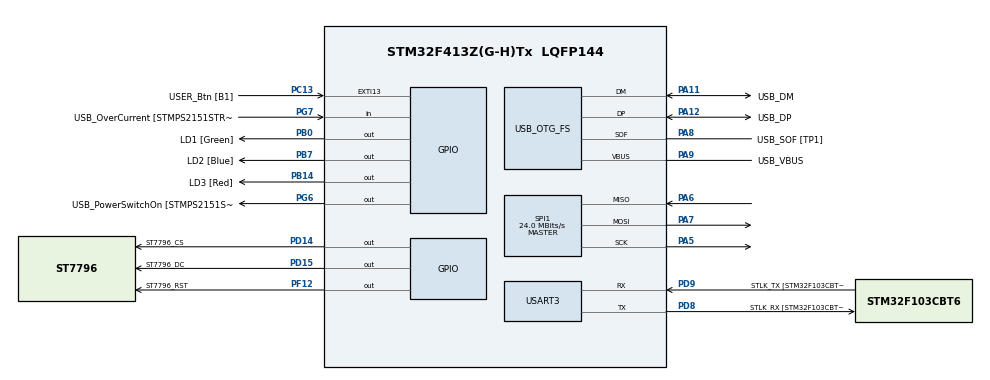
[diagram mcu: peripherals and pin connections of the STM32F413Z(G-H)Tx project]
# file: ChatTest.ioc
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Mcu.Family=STM32F4
Mcu.Name=STM32F413Z(G-H)Tx
Mcu.Package=LQFP144
NVIC.PriorityGroup=NVIC_PRIORITYGROUP_4
PA10.GPIO_Label=USB_ID
PA10.Signal=USB_OTG_FS_ID
PA11.GPIO_Label=USB_DM
PA11.Mode=Device_Only
PA11.Signal=USB_OTG_FS_DM
PA12.GPIO_Label=USB_DP
PA12.Mode=Device_Only
PA12.Signal=USB_OTG_FS_DP
PA13.GPIO_Label=TMS
PA13.Mode=Serial_Wire
PA13.Signal=SYS_JTMS-SWDIO
PA14.GPIO_Label=TCK
PA14.Mode=Serial_Wire
PA14.Signal=SYS_JTCK-SWCLK
PA5.Mode=Full_Duplex_Master
PA5.Signal=SPI1_SCK
PA6.Mode=Full_Duplex_Master
PA6.Signal=SPI1_MISO
PA7.Mode=Full_Duplex_Master
PA7.Signal=SPI1_MOSI
PA8.GPIO_Label=USB_SOF [TP1]
PA8.Mode=Activate_SOF_FS
PA8.Signal=USB_OTG_FS_SOF
PA9.GPIO_Label=USB_VBUS
PA9.Mode=Activate_VBUS
PA9.Signal=USB_OTG_FS_VBUS
PB0.GPIO_Label=LD1 [Green]
PB0.Signal=GPIO_Output
PB14.GPIO_Label=LD3 [Red]
PB14.Signal=GPIO_Output
PB3.GPIO_Label=SWO
PB3.Signal=SYS_JTDO-SWO
PB7.GPIO_Label=LD2 [Blue]
PB7.Signal=GPIO_Output
PC13.GPIO_Label=USER_Btn [B1]
PC13.Signal=GPXTI13
PC14-OSC32_IN.Mode=LSE-External-Oscillator
PC14-OSC32_IN.Signal=RCC_OSC32_IN
PC15-OSC32_OUT.Mode=LSE-External-Oscillator
PC15-OSC32_OUT.Signal=RCC_OSC32_OUT
PD14.GPIO_Label=ST7796_CS
PD14.Signal=GPIO_Output
PD15.GPIO_Label=ST7796_DC
PD15.Signal=GPIO_Output
PD8.GPIO_Label=STLK_RX [STM32F103CBT6_PA3]
PD8.Mode=Asynchronous
PD8.Signal=USART3_TX
PD9.GPIO_Label=STLK_TX [STM32F103CBT6_PA2]
PD9.Mode=Asynchronous
PD9.Signal=USART3_RX
PF12.GPIO_Label=ST7796_RST
PF12.Signal=GPIO_Output
PG6.GPIO_Label=USB_PowerSwitchOn [STMPS2151STR_EN]
PG6.Signal=GPIO_Output
PG7.GPIO_Label=USB_OverCurrent [STMPS2151STR_FAULT]
PG7.Signal=GPIO_Input
PH0\ -\ OSC_IN.GPIO_Label=MCO
PH0\ -\ OSC_IN.Mode=HSE-External-Clock-Source
PH0\ -\ OSC_IN.Signal=RCC_OSC_IN
PH1\ -\ OSC_OUT.Mode=HSE-External-Clock-Source
PH1\ -\ OSC_OUT.Signal=RCC_OSC_OUT
ProjectManager.HeapSize=0x200
ProjectManager.StackSize=0x400
ProjectManager.TargetToolchain=CMake
RCC.48MHZClocksFreq_Value=24000000
RCC.AHBFreq_Value=96000000
RCC.APB1CLKDivider=RCC_HCLK_DIV2
RCC.APB1Freq_Value=48000000
RCC.APB1TimFreq_Value=96000000
RCC.APB2Freq_Value=96000000
RCC.APB2TimFreq_Value=96000000
RCC.CortexFreq_Value=96000000
RCC.HCLKFreq_Value=96000000
RCC.HSE_VALUE=8000000
RCC.HSI_VALUE=16000000
RCC.PLLM=8
RCC.PLLMUL=RCC_PLL_MUL9
RCC.PLLN=384
RCC.PLLP=RCC_PLLP_DIV4
RCC.PLLQ=8
RCC.PRESCALERUSB=RCC_USBCLKSOURCE_PLL_DIV1_5
RCC.SYSCLKFreq_VALUE=96000000
RCC.SYSCLKSource=RCC_SYSCLKSOURCE_PLLCLK
RCC.SYSCLKSourceVirtual=RCC_SYSCLKSOURCE_PLLCLK
RCC.USBFreq_Value=48000000
RCC.VCOOutputFreq_Value=384000000
SPI1.BaudRatePrescaler=SPI_BAUDRATEPRESCALER_4
SPI1.CLKPhase=SPI_PHASE_1EDGE
SPI1.CLKPolarity=SPI_POLARITY_LOW
SPI1.CalculateBaudRate=24.0 MBits/s
SPI1.DataSize=SPI_DATASIZE_8BIT
SPI1.Direction=SPI_DIRECTION_2LINES
SPI1.FirstBit=SPI_FIRSTBIT_MSB
SPI1.Mode=SPI_MODE_MASTER
SPI1.NSS=SPI_NSS_SOFT
SPI1.VirtualType=VM_MASTER
USART3.VirtualMode=VM_ASYNC
USB_OTG_FS.VirtualMode=Device_Only
board=NUCLEO-F413ZH

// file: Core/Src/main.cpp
// Main application entry point and runtime-owned state.

/* USER CODE BEGIN Header */
/**
  ******************************************************************************
   * @file           : main.cpp
  * @brief          : Main program body
  ******************************************************************************
  * @attention
  *
  * Copyright (c) 2026 STMicroelectronics.
  * All rights reserved.
  *
  * This software is licensed under terms that can be found in the LICENSE file
  * in the root directory of this software component.
  * If no LICENSE file comes with this software, it is provided AS-IS.
  *
  ******************************************************************************
  */
/* USER CODE END Header */
#include "main.h"

/* USER CODE BEGIN Includes */
#include "app/app_runtime.h"
#include "app/app_startup.h"
/* USER CODE END Includes */

SPI_HandleTypeDef hspi1;

UART_HandleTypeDef huart3;

PCD_HandleTypeDef hpcd_USB_OTG_FS;

/* USER CODE BEGIN PV */
DMA_HandleTypeDef hdma_spi1_tx;
/* USER CODE END PV */

void SystemClock_Config(void);
static void MX_GPIO_Init(void);
static void MX_SPI1_Init(void);
static void MX_USART3_UART_Init(void);
static void MX_USB_OTG_FS_PCD_Init(void);

/* USER CODE BEGIN 0 */

extern "C" int __io_putchar(int ch)
{
  uint8_t byte = (uint8_t)ch;

  /* printf is routed to the ST-LINK virtual COM port when USART3 is alive,
   * giving lightweight debug output without involving the MIDI UART path. */
  if (huart3.Instance == USART3)
    HAL_UART_Transmit(&huart3, &byte, 1U, 10U);

  return ch;
}

/* USER CODE END 0 */

int main(void)
{

  /* MCU Configuration--------------------------------------------------------*/

  /* Reset of all peripherals, Initializes the Flash interface and the Systick. */
    HAL_Init();

  /* Configure the system clock */
  SystemClock_Config();

  /* Initialize all configured peripherals */
  MX_GPIO_Init();
  MX_SPI1_Init();
  MX_USART3_UART_Init();
  MX_USB_OTG_FS_PCD_Init();
  /* USER CODE BEGIN 2 */
  /* Board/application startup owns the higher-level hardware bring-up that
   * CubeMX does not model: runtime state, display, MIDI, storage, and UI. */
  AppStartup_Run();

  /* USER CODE END 2 */

  /* Infinite loop */
  while (1)
  {
    /* Keep the foreground loop thin so time-sensitive work can stay in the
     * app runtime/service layers instead of spreading through main(). */
    AppRuntime_ServiceForeground();
  }
}

static void MX_SPI1_Init(void)
{

  hspi1.Instance = SPI1;
  hspi1.Init.Mode = SPI_MODE_MASTER;
  hspi1.Init.Direction = SPI_DIRECTION_2LINES;
  hspi1.Init.DataSize = SPI_DATASIZE_8BIT;
  hspi1.Init.CLKPolarity = SPI_POLARITY_LOW;
  hspi1.Init.CLKPhase = SPI_PHASE_1EDGE;
  hspi1.Init.NSS = SPI_NSS_SOFT;
  hspi1.Init.BaudRatePrescaler = SPI_BAUDRATEPRESCALER_2;
  hspi1.Init.FirstBit = SPI_FIRSTBIT_MSB;
  hspi1.Init.TIMode = SPI_TIMODE_DISABLE;
  hspi1.Init.CRCCalculation = SPI_CRCCALCULATION_DISABLE;
  hspi1.Init.CRCPolynomial = 10;
  if (HAL_SPI_Init(&hspi1) != HAL_OK)
  {
    Error_Handler();
  }
}

void SystemClock_Config(void)
{
  /** Configure the main internal regulator output voltage */
  __HAL_RCC_PWR_CLK_ENABLE();
  __HAL_PWR_VOLTAGESCALING_CONFIG(PWR_REGULATOR_VOLTAGE_SCALE1);

  /* Boot from HSI first so standalone E5V startup does not depend on the
   * ST-LINK-side MCO becoming ready before main() runs. */
  if (AppStartup_RestoreHsiPll() != HAL_OK)
  {
    Error_Handler();
  }
}

static void MX_USART3_UART_Init(void)
{

  /* USER CODE BEGIN USART3_Init 1 */
 // This is the UART used for debug prints over the ST-Link USB interface. It is not used for MIDI output, which is brought up by the board-startup module before the UI starts sending MIDI messages.
  /* USER CODE END USART3_Init 1 */
  huart3.Instance = USART3;
  huart3.Init.BaudRate = 115200;
  huart3.Init.WordLength = UART_WORDLENGTH_8B;
  huart3.Init.StopBits = UART_STOPBITS_1;
  huart3.Init.Parity = UART_PARITY_NONE;
  huart3.Init.Mode = UART_MODE_TX_RX;
  huart3.Init.HwFlowCtl = UART_HWCONTROL_NONE;
  huart3.Init.OverSampling = UART_OVERSAMPLING_16;
  if (HAL_UART_Init(&huart3) != HAL_OK)
  {
    Error_Handler();
  }

}

static void MX_USB_OTG_FS_PCD_Init(void)
{

  hpcd_USB_OTG_FS.Instance = USB_OTG_FS;
  hpcd_USB_OTG_FS.Init.dev_endpoints = 6;
  hpcd_USB_OTG_FS.Init.speed = PCD_SPEED_FULL;
  hpcd_USB_OTG_FS.Init.dma_enable = DISABLE;
  hpcd_USB_OTG_FS.Init.phy_itface = PCD_PHY_EMBEDDED;
  hpcd_USB_OTG_FS.Init.Sof_enable = ENABLE;
  hpcd_USB_OTG_FS.Init.low_power_enable = DISABLE;
  hpcd_USB_OTG_FS.Init.lpm_enable = DISABLE;
  hpcd_USB_OTG_FS.Init.battery_charging_enable = ENABLE;
  hpcd_USB_OTG_FS.Init.vbus_sensing_enable = ENABLE;
  hpcd_USB_OTG_FS.Init.use_dedicated_ep1 = DISABLE;
  if (HAL_PCD_Init(&hpcd_USB_OTG_FS) != HAL_OK)
  {
    Error_Handler();
  }

}

static void MX_GPIO_Init(void)
{
  GPIO_InitTypeDef GPIO_InitStruct = {0};

  /* GPIO Ports Clock Enable */
  __HAL_RCC_GPIOC_CLK_ENABLE();
  __HAL_RCC_GPIOH_CLK_ENABLE();
  __HAL_RCC_GPIOB_CLK_ENABLE();
  __HAL_RCC_GPIOD_CLK_ENABLE();
  __HAL_RCC_GPIOE_CLK_ENABLE();
  __HAL_RCC_GPIOF_CLK_ENABLE();
  __HAL_RCC_GPIOG_CLK_ENABLE();
  __HAL_RCC_GPIOA_CLK_ENABLE();

  /*Configure GPIO pin Output Level */
  HAL_GPIO_WritePin(GPIOB, LD1_Pin|LD3_Pin|LD2_Pin, GPIO_PIN_RESET);

  /*Configure GPIO pin Output Level */
  HAL_GPIO_WritePin(USB_PowerSwitchOn_GPIO_Port, USB_PowerSwitchOn_Pin, GPIO_PIN_RESET);

  /*Configure GPIO pins : LD1_Pin LD3_Pin LD2_Pin */
  GPIO_InitStruct.Pin = LD1_Pin|LD3_Pin|LD2_Pin;
  GPIO_InitStruct.Mode = GPIO_MODE_OUTPUT_PP;
  GPIO_InitStruct.Pull = GPIO_NOPULL;
  GPIO_InitStruct.Speed = GPIO_SPEED_FREQ_LOW;
  HAL_GPIO_Init(GPIOB, &GPIO_InitStruct);

  /*Configure GPIO pin : USB_PowerSwitchOn_Pin */
  GPIO_InitStruct.Pin = USB_PowerSwitchOn_Pin;
  GPIO_InitStruct.Mode = GPIO_MODE_OUTPUT_PP;
  GPIO_InitStruct.Pull = GPIO_NOPULL;
  GPIO_InitStruct.Speed = GPIO_SPEED_FREQ_LOW;
  HAL_GPIO_Init(USB_PowerSwitchOn_GPIO_Port, &GPIO_InitStruct);

  /*Configure GPIO pin : USB_OverCurrent_Pin */
  GPIO_InitStruct.Pin = USB_OverCurrent_Pin;
  GPIO_InitStruct.Mode = GPIO_MODE_INPUT;
  GPIO_InitStruct.Pull = GPIO_NOPULL;
  HAL_GPIO_Init(USB_OverCurrent_GPIO_Port, &GPIO_InitStruct);

}

void Error_Handler(void)
{
  __disable_irq();
  while (1)
  {
  }
}
